# STM32F745 register map
File version: 1.6
CPU: CM7 r0p1, little endian, MPU, FPU, 4 interrupt priority bits
Registers are 32-bit, read-write, reset 0x0 unless marked. A register's access mark holds for its fields unless they carry their own. Offsets are from the block's base; [hi:lo] are bit positions; {n}, {i} and the like mark numbered series; 'fields as' and 'values as' point back to an identical list.

## DBGMCU — Debug support
Base 0xE0042000
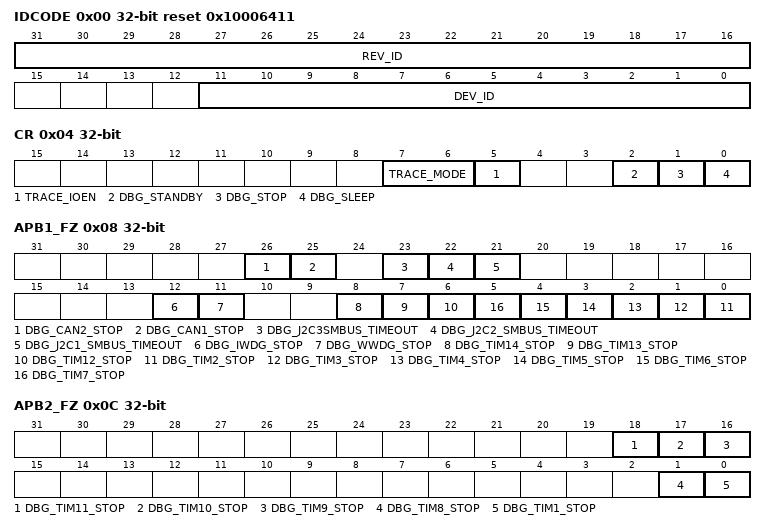
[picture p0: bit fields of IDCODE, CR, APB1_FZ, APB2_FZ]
0x00 IDCODE ro reset 0x10006411
  [31:16] REV_ID, [11:0] DEV_ID
0x04 CR — Control Register
  [7:6] TRACE_MODE
    0=Asynchronous (TRACE pin assignment for Asynchronous Mode); 1=Size1 (TRACE pin assignment for Synchronous Mode with a TRACEDATA size of 1); 2=Size2 (TRACE pin assignment for Synchronous Mode with a TRACEDATA size of 2); 3=Size4 (TRACE pin assignment for Synchronous Mode with a TRACEDATA size of 4)
  [5] TRACE_IOEN
    0=Disabled (Trace pins not assigned (default state)); 1=Enabled (Trace pins assigned)
  [2] DBG_STANDBY
  [1] DBG_STOP
  [0] DBG_SLEEP
0x08 APB1_FZ — Debug MCU APB1 Freeze registe
  [26] DBG_CAN2_STOP
  [25] DBG_CAN1_STOP
  [23] DBG_J2C3SMBUS_TIMEOUT
  [22] DBG_J2C2_SMBUS_TIMEOUT
  [21] DBG_J2C1_SMBUS_TIMEOUT
  [12] DBG_IWDG_STOP — DBG_IWDEG_STOP
  [11] DBG_WWDG_STOP
  [8] DBG_TIM14_STOP
  [7] DBG_TIM13_STOP
  [6] DBG_TIM12_STOP
  [n-2] DBG_TIM{n}_STOP (n=2..7)
0x0C APB2_FZ — Debug MCU APB2 Freeze registe
  [18] DBG_TIM11_STOP — TIM11 counter stopped when core is halted
  [17] DBG_TIM10_STOP — TIM10 counter stopped when core is halted
  [16] DBG_TIM9_STOP — TIM9 counter stopped when core is halted
  [1] DBG_TIM8_STOP — TIM8 counter stopped when core is halted
  [0] DBG_TIM1_STOP — TIM1 counter stopped when core is halted

## SYSCFG — System configuration controller
Base 0x40013800
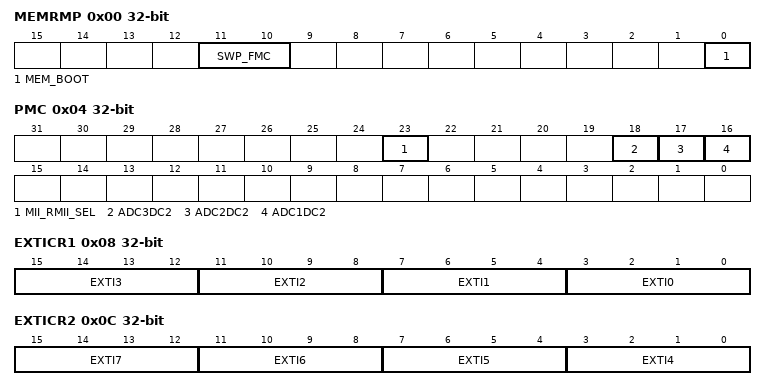
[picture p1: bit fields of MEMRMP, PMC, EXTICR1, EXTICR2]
0x00 MEMRMP — memory remap register
  [11:10] SWP_FMC — FMC memory mapping swap
    0=NoSwap (No FMC memory mapping swap); 1=Swapped (SDRAM banks and NOR/RAM mapping are swapped)
  [0] MEM_BOOT — Memory mapping selection
    0=Add0 (Boot memory base address is defined by FLASH.OPTCR1.BOOT_ADD0); 1=Add1 (Boot memory base address is defined by FLASH.OPTCR1.BOOT_ADD1)
0x04 PMC — peripheral mode configuration register
  [23] MII_RMII_SEL — Ethernet PHY interface selection
    0=MII (MII interface is selected); 1=RMII_PHY (RMII PHY interface is selected)
  [18] ADC3DC2
  [17] ADC2DC2
  [16] ADC1DC2
0x08 EXTICR1 — external interrupt configuration register 1
  [all] fields
    0=PA (Select PAx as the source input for the EXTIx external interrupt); 1=PB (Select PBx as the source input for the EXTIx external interrupt); 2=PC (Select PCx as the source input for the EXTIx external interrupt); 3=PD (Select PDx as the source input for the EXTIx external interrupt); 4=PE (Select PEx as the source input for the EXTIx external interrupt); 5=PF (Select PFx as the source input for the EXTIx external interrupt); 6=PG (Select PGx as the source input for the EXTIx external interrupt); 7=PH (Select PHx as the source input for the EXTIx external interrupt); 8=PI (Select PIx as the source input for the EXTIx external interrupt); 9=PJ (Select PJx as the source input for the EXTIx external interrupt); 10=PK (Select PKx as the source input for the EXTIx external interrupt)
  [4n+3:4n] EXTI{n} (n=0..3) — EXTI x configuration (x = 0 to 3)
0x0C EXTICR2 — external interrupt configuration register 2
  [all] fields
    values as the fields of EXTICR1
  [4n-13:4n-16] EXTI{n} (n=4..7) — EXTI x configuration (x = 4 to 7)
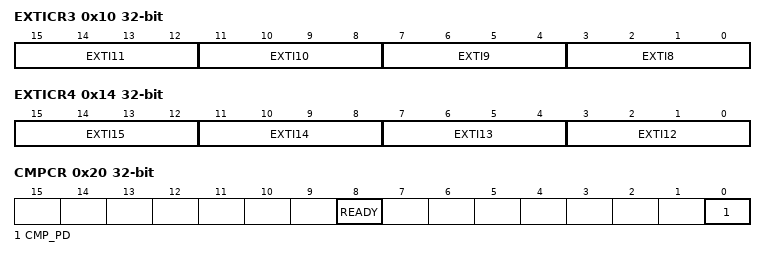
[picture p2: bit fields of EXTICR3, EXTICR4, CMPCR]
0x10 EXTICR3 — external interrupt configuration register 3
  [all] fields
    values as the fields of EXTICR1
  [15:12] EXTI11 — EXTI x configuration (x = 8 to 11)
  [11:8] EXTI10
  [7:4] EXTI9 — EXTI x configuration (x = 8 to 11)
  [3:0] EXTI8 — EXTI x configuration (x = 8 to 11)
0x14 EXTICR4 — external interrupt configuration register 4
  [all] fields
    values as the fields of EXTICR1
  [4n-45:4n-48] EXTI{n} (n=12..15) — EXTI x configuration (x = 12 to 15)
0x20 CMPCR ro — Compensation cell control register
  [8] READY
    0=NotReady (I/O compensation cell not ready); 1=Ready (I/O compensation cell ready)
  [0] CMP_PD — Compensation cell power-down
    0=PowerDown (I/O compensation cell power-down mode); 1=Enabled (I/O compensation cell enabled)
